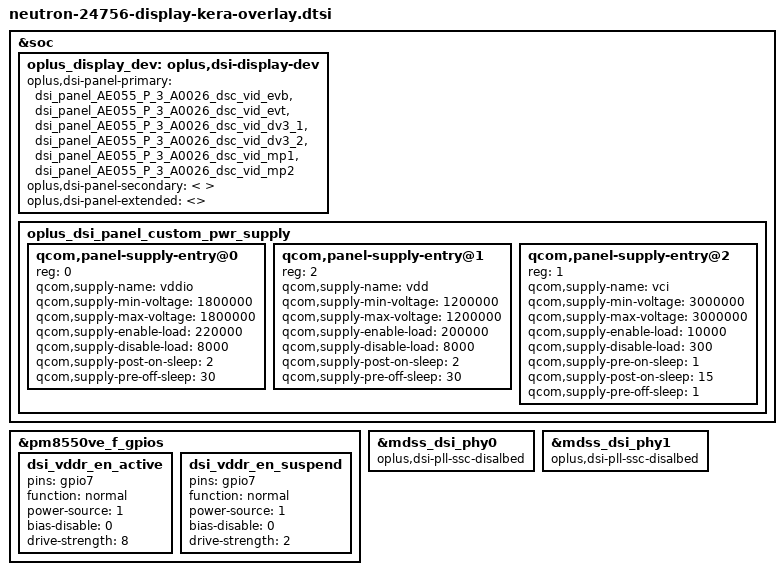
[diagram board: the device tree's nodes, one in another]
#include "panel/dsi-panel-AE055-P-3-A0026-dsc-vid-evb.dtsi"
#include "panel/dsi-panel-AE055-P-3-A0026-dsc-vid-evt.dtsi"
#include "panel/dsi-panel-AE055-P-3-A0026-dsc-vid-dv3-1.dtsi"
#include "panel/dsi-panel-AE055-P-3-A0026-dsc-vid-dv3-2.dtsi"
#include "panel/dsi-panel-AE055-P-3-A0026-dsc-vid-mp1.dtsi"
#include "panel/dsi-panel-AE055-P-3-A0026-dsc-vid-mp2.dtsi"

&soc {
	oplus_display_dev: oplus,dsi-display-dev {
		oplus,dsi-panel-primary = <
			&dsi_panel_AE055_P_3_A0026_dsc_vid_evb
			&dsi_panel_AE055_P_3_A0026_dsc_vid_evt
			&dsi_panel_AE055_P_3_A0026_dsc_vid_dv3_1
			&dsi_panel_AE055_P_3_A0026_dsc_vid_dv3_2
			&dsi_panel_AE055_P_3_A0026_dsc_vid_mp1
			&dsi_panel_AE055_P_3_A0026_dsc_vid_mp2
		>;
		oplus,dsi-panel-secondary = <
		>;
		oplus,dsi-panel-extended = <>;
	};


	oplus_dsi_panel_custom_pwr_supply: oplus_dsi_panel_custom_pwr_supply {
		#address-cells = <1>;
		#size-cells = <0>;
		qcom,panel-supply-entry@0 {
			reg = <0>;
			qcom,supply-name = "vddio";
			qcom,supply-min-voltage = <1800000>;
			qcom,supply-max-voltage = <1800000>;
			qcom,supply-enable-load = <220000>;
			qcom,supply-disable-load = <8000>;
			qcom,supply-post-on-sleep = <2>;
			qcom,supply-pre-off-sleep = <30>;
		};

		qcom,panel-supply-entry@1 {
			reg = <2>;
			qcom,supply-name = "vdd";
			qcom,supply-min-voltage = <1200000>;
			qcom,supply-max-voltage = <1200000>;
			qcom,supply-enable-load = <200000>;
			qcom,supply-disable-load = <8000>;
			qcom,supply-post-on-sleep = <2>;
			qcom,supply-pre-off-sleep = <30>;
		};

		qcom,panel-supply-entry@2 {
			reg = <1>;
			qcom,supply-name = "vci";
			qcom,supply-min-voltage = <3000000>;
			qcom,supply-max-voltage = <3000000>;
			qcom,supply-enable-load = <10000>;
			qcom,supply-disable-load = <300>;
			qcom,supply-pre-on-sleep = <1>;
			qcom,supply-post-on-sleep = <15>;
			qcom,supply-pre-off-sleep = <1>;
		};

	};
};

&pm8550ve_f_gpios {
	dsi_vddr_en_active: dsi_vddr_en_active {
		pins = "gpio7";
		function = "normal";
		power-source = <1>; /* 1.8V */
		bias-disable = <0>;   /* no pull */
		drive-strength = <8>;  /* 8 mA */
	};

	dsi_vddr_en_suspend: dsi_vddr_en_suspend  {
		pins = "gpio7";
		function = "normal";
		power-source = <1>; /* 1.8V */
		bias-disable = <0>;   /* no pull */
		drive-strength = <2>;  /* 2 mA */
	};
};

/* #ifdef OPLUS_FEATURE_DISPLAY */
&mdss_dsi_phy0 {
	oplus,dsi-pll-ssc-disalbed;
};

&mdss_dsi_phy1 {
	oplus,dsi-pll-ssc-disalbed;
};
/* OPLUS_FEATURE_DISPLAY */

